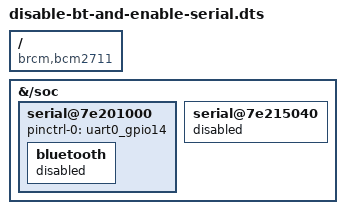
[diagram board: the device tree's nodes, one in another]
/dts-v1/;
/plugin/;

/ {
    compatible = "brcm,bcm2711";

    fragment@0 {
        target-path = "/soc";
        __overlay__ {
            serial@7e201000 {
                pinctrl-0 = <&uart0_gpio14>;
                bluetooth {
                    status = "disabled";
                };
            };

            serial@7e215040 {
                status = "disabled";
            };
        };
    };
};
